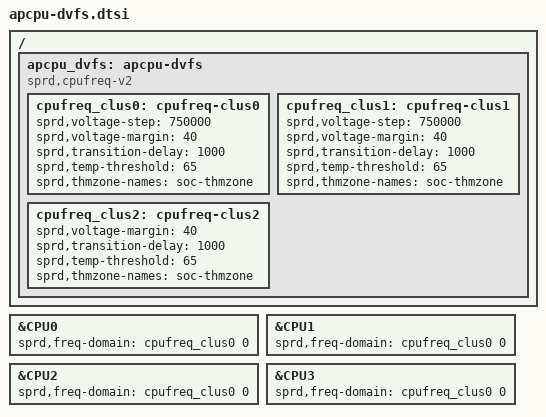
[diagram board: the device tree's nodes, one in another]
// SPDX-License-Identifier: (GPL-2.0+ OR MIT)
/*
 * Unisoc APCPU DVFS dts file
 *
 * Copyright (C) 2022, Unisoc Communications Inc.
 *
 */

&CPU0 {
	sprd,freq-domain = <&cpufreq_clus0 0>;
};

&CPU1 {
	sprd,freq-domain = <&cpufreq_clus0 0>;
};

&CPU2 {
	sprd,freq-domain = <&cpufreq_clus0 0>;
};

&CPU3 {
	sprd,freq-domain = <&cpufreq_clus0 0>;
};

/ {
	apcpu_dvfs: apcpu-dvfs {
		compatible = "sprd,cpufreq-v2";

		cpufreq_clus0: cpufreq-clus0 {
			sprd,voltage-step = <750000>;           /* uV       */
			sprd,voltage-margin = <40>;             /* Cycle    */
			sprd,transition-delay = <1000>;         /* us       */
			sprd,temp-threshold = <65>;             /* u32 list */
			sprd,thmzone-names = "soc-thmzone";
			#freq-domain-cells = <1>;
		};

		cpufreq_clus1: cpufreq-clus1 {
			sprd,voltage-step = <750000>;           /* uV       */
			sprd,voltage-margin = <40>;             /* Cycle    */
			sprd,transition-delay = <1000>;         /* us       */
			sprd,temp-threshold = <65>;             /* u32 list */
			sprd,thmzone-names = "soc-thmzone";
			#freq-domain-cells = <1>;
		};

		cpufreq_clus2: cpufreq-clus2 {
			sprd,voltage-margin = <40>;             /* Cycle    */
			sprd,transition-delay = <1000>;         /* us       */
			sprd,temp-threshold = <65>;             /* u32 list */
			sprd,thmzone-names = "soc-thmzone";
			#freq-domain-cells = <1>;
		};
	};
};
